# STM32F779xx register map
File version: 1.0
Registers are 32-bit, read-write, reset 0x0 unless marked. A register's access mark holds for its fields unless they carry their own. Offsets are from the block's base; [hi:lo] are bit positions; {n}, {i} and the like mark numbered series.

## TIM6 — TIM
Base 0x40001000
Same registers: TIM7 0x40001400
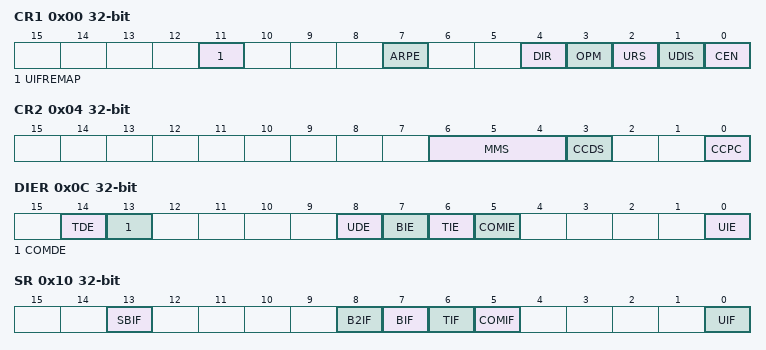
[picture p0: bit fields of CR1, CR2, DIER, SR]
0x00 CR1 — TIM control register 1
  [11] UIFREMAP — UIF status bit
  [7] ARPE — Auto-reload preload enable
  [4] DIR — Direction
    0=UP (Timer counter counts up); 1=DOWN (Timer counter counts down)
  [3] OPM — One pulse mode
    1=SINGLE (Counter stops counting at the next update event); 0=REPETITIVE (Counter is not stopped at update event)
  [2] URS — Update request source
    0=REGULAR (Counter overflow/underflow, Setting the UG bit or Update generation through the slave mode controller generates an update request); 1=COUNTER (Only counter overflow/underflow generates an update request)
  [1] UDIS — Update disable
  [0] CEN — Counter enable
0x04 CR2 — TIM control register 2
  [6:4] MMS — MMS[2:0] bits (Master Mode Selection)
    0=RESET (UG bit from the TIMx_EGR register is used as trigger output); 1=ENABLE (Counter Enable signal (CNT_EN) is used as trigger output); 2=UPDATE (Update event is used as trigger output); 3=CC1IF (CC1 capture or a compare match is used as trigger output); {v}=OC{v-3}REF (OC{v-3}REF signal is used as trigger output) (v=4..7)
  [3] CCDS — Capture/Compare DMA Selection
    0=CC (CCx DMA request sent when CCx event occurs); 1=UPDATE (CCx DMA requests sent when update event occurs)
  [0] CCPC — Capture/Compare Preloaded Control
0x0C DIER — TIM DMA/interrupt enable register
  [14] TDE — Trigger DMA request enable
  [13] COMDE — COM DMA request enable
  [8] UDE — Update DMA request enable
  [7] BIE — Break interrupt enable
  [6] TIE — Trigger interrupt enable
  [5] COMIE — COM interrupt enable
  [0] UIE — Update interrupt enable
0x10 SR — TIM status register
  [13] SBIF — System Break interrupt Flag
  [8] B2IF — Break2 interrupt Flag
  [7] BIF — Break interrupt Flag
  [6] TIF — Trigger interrupt Flag
  [5] COMIF — COM interrupt Flag
  [0] UIF — Update interrupt Flag
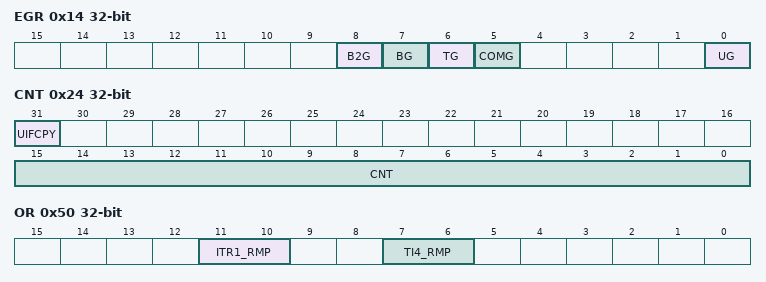
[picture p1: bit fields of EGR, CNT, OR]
0x14 EGR — TIM event generation register
  [8] B2G — Break2 Generation
  [7] BG — Break Generation
  [6] TG — Trigger Generation
  [5] COMG — Capture/Compare Control Update Generation
  [0] UG — Update Generation
0x24 CNT — TIM counter register
  [31] UIFCPY — Update interrupt flag copy (if UIFREMAP=1)
  [15:0] CNT — Counter Value
0x28 PSC — TIM prescaler
  [15:0] PSC — Prescaler Value
0x2C ARR — TIM auto-reload register
  [15:0] ARR — actual auto-reload Value
0x4C DMAR — TIM DMA address for full transfer
  [15:0] DMAB — DMA register for burst accesses
0x50 OR — TIM option register
  [11:10] ITR1_RMP — ITR1_RMP[1:0] bits (TIM2 Internal trigger 1 remap)
  [7:6] TI4_RMP — TI4_RMP[1:0] bits (TIM5 Input 4 remap)
0x5C CCR6 — TIM capture/compare mode register6
0x60 AF1 — TIM Alternate function option register 1
0x64 AF2 — TIM Alternate function option register 2

## WWDG — Window WATCHDOG
Base 0x40002C00
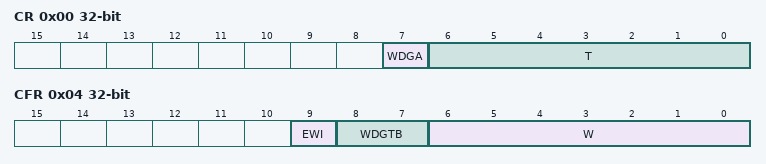
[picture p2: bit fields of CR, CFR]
0x00 CR — WWDG Control register
  [7] WDGA — Activation bit
  [6:0] T — T[6:0] bits (7-Bit counter (MSB to LSB))
0x04 CFR — WWDG Configuration register
  [9] EWI — Early Wakeup Interrupt
  [8:7] WDGTB — WDGTB[1:0] bits (Timer Base)
    0=PRESCALER_1 (WWDG counter clock = (PCLK1/4096)/1); 1=PRESCALER_2 (WWDG counter clock = (PCLK1/4096)/2); 2=PRESCALER_4 (WWDG counter clock = (PCLK1/4096)/4); 3=PRESCALER_8 (WWDG counter clock = (PCLK1/4096)/8)
  [6:0] W — W[6:0] bits (7-bit window value)
0x08 SR — WWDG Status register
  [0] EWIF — Early Wakeup Interrupt Flag

## IWDG — Independent WATCHDOG
Base 0x40003000
0x00 KR — IWDG Key register
  [15:0] KEY — Key value (write only, read 0000h)
0x04 PR — IWDG Prescaler register
  [2:0] PR — PR[2:0] (Prescaler divider)
0x08 RLR — IWDG Reload register
  [11:0] RL — Watchdog counter reload value
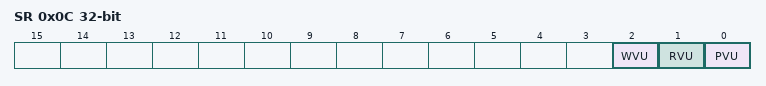
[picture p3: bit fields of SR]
0x0C SR — IWDG Status register
  [2] WVU — Watchdog counter window value update
  [1] RVU — Watchdog counter reload value update
  [0] PVU — Watchdog prescaler value update
0x10 WINR — IWDG Window register
  [11:0] WIN — Watchdog counter window value
